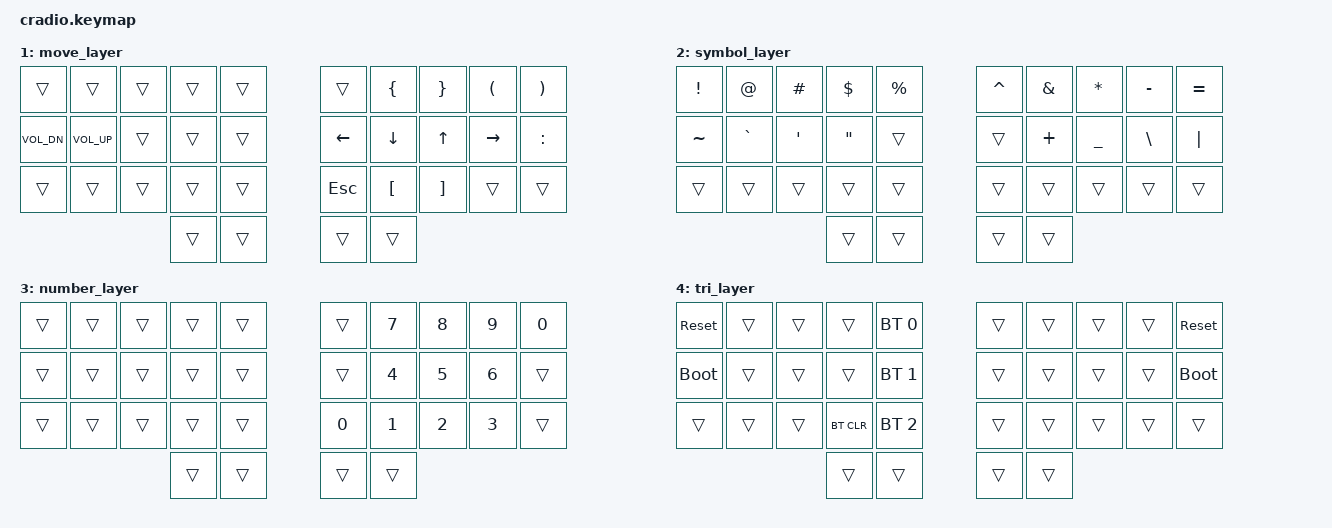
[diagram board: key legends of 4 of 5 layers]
// Copyright (c) 2022 The ZMK Contributors
// SPDX-License-Identifier: MIT

#include <behaviors.dtsi>
#include <dt-bindings/zmk/keys.h>
#include <dt-bindings/zmk/bt.h>

// Home row mods macro
#define HRML(k1,k2,k3,k4) &hrm LGUI k1  &hrm LALT k2  &hrm LSHFT k3  &hrm LCTRL k4
#define HRMR(k1,k2,k3,k4) &hrm RCTRL k1  &hrm RSHFT k2  &hrm RALT k3  &hrm RGUI k4

/ {
    behaviors {
        hrm: hold_tap {
            compatible = "zmk,behavior-hold-tap";
            flavor = "balanced";
            tapping-term-ms = <280>;
            quick-tap-ms = <175>;
            require-prior-idle-ms = <75>;
            bindings = <&kp>, <&kp>;
            #binding-cells = <2>;
        };

        lt: layer_tap {
            compatible = "zmk,behavior-hold-tap";
            flavor = "balanced";
            tapping-term-ms = <280>;
            quick-tap-ms = <175>;
            require-prior-idle-ms = <75>;
            #binding-cells = <2>;
            bindings = <&mo>, <&kp>;
            display-name = "Layer-Tap";
        };
    };

    conditional_layers {
        compatible = "zmk,conditional-layers";
        tri_layer {
            if-layers = <1 2>;
            then-layer = <4>;
        };
    };

    keymap {
        compatible = "zmk,keymap";
        default_layer {
            bindings = <
        //╭──────────┬──────────┬──────────┬──────────┬──────────╮   ╭──────────┬──────────┬──────────┬──────────┬──────────╮
        //│  Q       │  W       │  E       │  R       │  T       │   │  Y       │  U       │  I       │  O       │  P       │
            &kp Q      &kp W      &kp E      &kp R      &kp T          &kp Y      &kp U      &kp I      &kp O      &kp P
        //├──────────┼──────────┼──────────┼──────────┼──────────┤   ├──────────┼──────────┼──────────┼──────────┼──────────┤
        //│  A       │  S       │  D       │  F       │  G       │   │  H       │  J       │  K       │  L       │   ;      │
            HRML(A,        S,         D,         F)     &kp G          &kp H      HRMR(J,        K,         L,        SEMI)
        //├──────────┼──────────┼──────────┼──────────┼──────────┤   ├──────────┼──────────┼──────────┼──────────┼──────────┤
        //│  Z       │  X       │  C       │  V       │  B       │   │  N       │  M       │ , <      │ . >      │ / ?      │
            &kp Z      &kp X      &kp C      &kp V      &kp B          &kp N      &kp M      &kp COMMA  &kp DOT    &kp FSLH
        //╰──────────┴──────────┴──────────┼──────────┼──────────┤   ├──────────┼──────────┼──────────┴──────────┴──────────╯
                                            &lt 3 TAB  &lt 1 SPACE   &lt 2 ENTER  &kp BSPC
        //                                 ╰──────────┴──────────╯   ╰──────────┴──────────╯
            >;
        };

        move_layer {
            bindings = <
        //╭──────────┬──────────┬──────────┬──────────┬──────────╮   ╭──────────┬──────────┬──────────┬──────────┬──────────╮
        //│          │          │          │          │          │   │          │    {     │    }     │     (    │    )     │
             &trans     &trans     &trans     &trans     &trans         &trans    &kp LBRC  &kp RBRC    &kp LPAR    &kp RPAR
        //├──────────┼──────────┼──────────┼──────────┼──────────┤   ├──────────┼──────────┼──────────┼──────────┼──────────┤
        //│          │          │          │          │          │   │          │          │          │          │     :    │
         &kp C_VOL_DN &kp C_VOL_UP &trans     &trans     &trans        &kp LEFT   &kp DOWN    &kp UP    &kp RIGHT  &kp COLON
        //├──────────┼──────────┼──────────┼──────────┼──────────┤   ├──────────┼──────────┼──────────┼──────────┼──────────┤
        //│          │          │          │          │          │   │          │    [     │    ]     │          │          │
             &trans     &trans     &trans     &trans     &trans         &kp ESC   &kp LBKT   &kp RBKT    &trans     &trans
        //╰──────────┴──────────┴──────────┼──────────┼──────────┤   ├──────────┼──────────┼──────────┴──────────┴──────────╯
                                              &trans     &trans         &trans     &trans
        //                                 ╰──────────┴──────────╯   ╰──────────┴──────────╯
            >;
        };

        symbol_layer {
            bindings = <
        //╭──────────┬──────────┬──────────┬──────────┬──────────╮   ╭──────────┬──────────┬──────────┬──────────┬──────────╮
        //│    !     │     @    │    #     │    $     │    %     │   │     ^    │    &     │    *     │    -     │    =     │
            &kp EXCL     &kp AT    &kp HASH  &kp DLLR   &kp PRCNT     &kp CARET   &kp AMPS  &kp ASTRK  &kp MINUS  &kp EQUAL
        //├──────────┼──────────┼──────────┼──────────┼──────────┤   ├──────────┼──────────┼──────────┼──────────┼──────────┤
        //│    ~     │    `     │    '     │    "     │          │   │          │    +     │    _     │    \     │    |     │
           &kp TILDE  &kp GRAVE   &kp SQT    &kp DQT     &trans         &trans    &kp PLUS  &kp UNDER   &kp BSLH   &kp PIPE
        //├──────────┼──────────┼──────────┼──────────┼──────────┤   ├──────────┼──────────┼──────────┼──────────┼──────────┤
             &trans     &trans     &trans     &trans     &trans         &trans     &trans     &trans     &trans     &trans
        //╰──────────┴──────────┴──────────┼──────────┼──────────┤   ├──────────┼──────────┼──────────┴──────────┴──────────╯
                                              &trans     &trans         &trans     &trans
        //                                 ╰──────────┴──────────╯   ╰──────────┴──────────╯
            >;
        };

        number_layer {
            bindings = <
        //╭──────────┬──────────┬──────────┬──────────┬──────────╮   ╭──────────┬──────────┬──────────┬──────────┬──────────╮
             &trans     &trans     &trans     &trans     &trans         &trans     &kp N7     &kp N8     &kp N9     &kp N0
        //├──────────┼──────────┼──────────┼──────────┼──────────┤   ├──────────┼──────────┼──────────┼──────────┼──────────┤
             &trans     &trans     &trans     &trans     &trans         &trans     &kp N4     &kp N5     &kp N6     &trans
        //├──────────┼──────────┼──────────┼──────────┼──────────┤   ├──────────┼──────────┼──────────┼──────────┼──────────┤
             &trans     &trans     &trans     &trans     &trans         &kp N0     &kp N1     &kp N2     &kp N3     &trans
        //╰──────────┴──────────┴──────────┼──────────┼──────────┤   ├──────────┼──────────┼──────────┴──────────┴──────────╯
                                              &trans     &trans         &trans     &trans
        //                                 ╰──────────┴──────────╯   ╰──────────┴──────────╯
            >;
        };

        tri_layer {
            bindings = <
        //╭──────────┬──────────┬──────────┬──────────┬──────────╮   ╭──────────┬──────────┬──────────┬──────────┬──────────╮
        //│ RESET    │          │          │          │          │   │          │          │          │          │  RESET   │
           &sys_reset  &trans     &trans     &trans    &bt BT_SEL 0    &trans     &trans     &trans     &trans    &sys_reset
        //├──────────┼──────────┼──────────┼──────────┼──────────┤   ├──────────┼──────────┼──────────┼──────────┼──────────┤
        //│BOOTLOADER│          │          │          │          │   │          │          │          │          │BOOTLOADER│
          &bootloader  &trans     &trans     &trans    &bt BT_SEL 1    &trans     &trans     &trans     &trans    &bootloader
        //├──────────┼──────────┼──────────┼──────────┼──────────┤   ├──────────┼──────────┼──────────┼──────────┼──────────┤
        //│          │          │          │ CLEAR BT │          │   │          │          │          │          │          │
            &trans     &trans     &trans    &bt BT_CLR &bt BT_SEL 2    &trans     &trans     &trans     &trans     &trans
        //╰──────────┴──────────┴──────────┼──────────┼──────────┤   ├──────────┼──────────┼──────────┴──────────┴──────────╯
                                             &trans     &trans         &trans     &trans
        //                                 ╰──────────┴──────────╯   ╰──────────┴──────────╯
            >;
        };
    };
};
